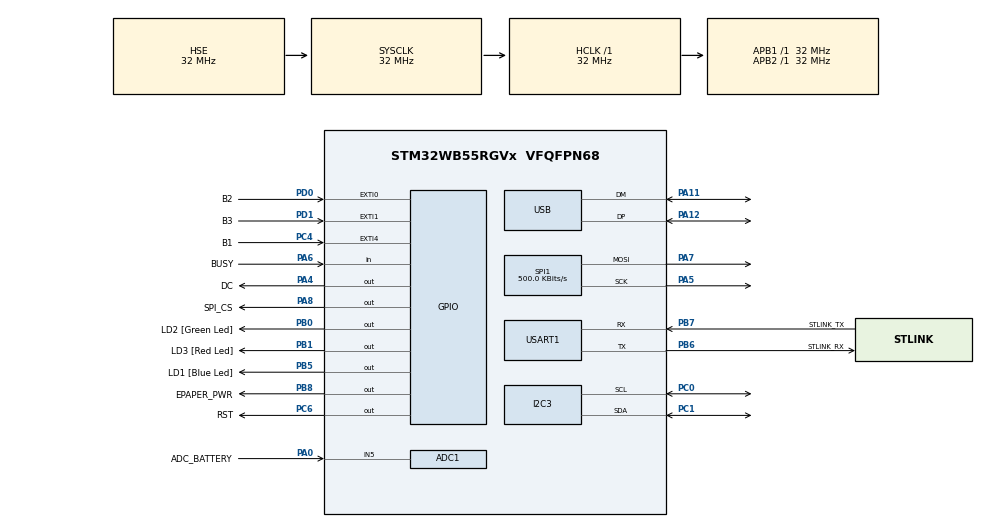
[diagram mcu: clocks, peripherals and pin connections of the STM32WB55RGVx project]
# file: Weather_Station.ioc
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ADC1.Channel-0\#ChannelRegularConversion=ADC_CHANNEL_5
ADC1.LowPowerAutoWait=ENABLE
ADC1.NbrOfConversionFlag=1
ADC1.OffsetNumber-0\#ChannelRegularConversion=ADC_OFFSET_NONE
ADC1.Overrun=ADC_OVR_DATA_OVERWRITTEN
ADC1.Rank-0\#ChannelRegularConversion=1
ADC1.SamplingTime-0\#ChannelRegularConversion=ADC_SAMPLETIME_2CYCLES_5
ADC1.master=1
Dma.Request0=USART1_RX
Dma.USART1_RX.0.Direction=DMA_PERIPH_TO_MEMORY
Dma.USART1_RX.0.EventEnable=DISABLE
Dma.USART1_RX.0.Instance=DMA1_Channel1
Dma.USART1_RX.0.MemDataAlignment=DMA_MDATAALIGN_BYTE
Dma.USART1_RX.0.MemInc=DMA_MINC_ENABLE
Dma.USART1_RX.0.Mode=DMA_NORMAL
Dma.USART1_RX.0.PeriphDataAlignment=DMA_PDATAALIGN_BYTE
Dma.USART1_RX.0.PeriphInc=DMA_PINC_DISABLE
Dma.USART1_RX.0.Polarity=HAL_DMAMUX_REQ_GEN_RISING
Dma.USART1_RX.0.Priority=DMA_PRIORITY_LOW
Dma.USART1_RX.0.RequestNumber=1
Dma.USART1_RX.0.SignalID=NONE
Dma.USART1_RX.0.SyncEnable=DISABLE
Dma.USART1_RX.0.SyncPolarity=HAL_DMAMUX_SYNC_NO_EVENT
Dma.USART1_RX.0.SyncRequestNumber=1
Dma.USART1_RX.0.SyncSignalID=NONE
I2C3.Timing=0x00707CBB
Mcu.Family=STM32WB
Mcu.Name=STM32WB55RGVx
Mcu.Package=VFQFPN68
NVIC.DMA1_Channel1_IRQn=true\:0\:0\:false\:false\:true\:false\:true\:true
NVIC.EXTI0_IRQn=true\:0\:1\:false\:false\:true\:true\:true\:true
NVIC.EXTI1_IRQn=true\:0\:1\:false\:false\:true\:true\:true\:true
NVIC.EXTI4_IRQn=true\:0\:1\:false\:false\:true\:true\:true\:true
NVIC.PriorityGroup=NVIC_PRIORITYGROUP_3
NVIC.RTC_Alarm_IRQn=true\:2\:1\:true\:true\:true\:1\:true\:true\:true
NVIC.TIM1_TRG_COM_TIM17_IRQn=true\:1\:0\:true\:false\:true\:true\:true\:true
NVIC.USART1_IRQn=true\:1\:1\:true\:false\:true\:true\:true\:true
OSC_IN.Mode=HSE-External-Oscillator
OSC_IN.Signal=RCC_OSC_IN
OSC_OUT.Mode=HSE-External-Oscillator
OSC_OUT.Signal=RCC_OSC_OUT
PA0.GPIO_Label=ADC_BATTERY
PA0.Signal=ADCx_IN5
PA11.Mode=Device
PA11.Signal=USB_DM
PA12.Mode=Device
PA12.Signal=USB_DP
PA13.GPIO_Label=JTMS
PA13.Mode=Trace_Asynchronous_SW
PA13.Signal=SYS_JTMS-SWDIO
PA14.GPIO_Label=JTCK
PA14.Mode=Trace_Asynchronous_SW
PA14.Signal=SYS_JTCK-SWCLK
PA4.GPIO_Label=DC
PA4.Signal=GPIO_Output
PA5.Mode=TX_Only_Simplex_Unidirect_Master
PA5.Signal=SPI1_SCK
PA6.GPIO_Label=BUSY
PA6.Signal=GPIO_Input
PA7.Mode=TX_Only_Simplex_Unidirect_Master
PA7.Signal=SPI1_MOSI
PA8.GPIO_Label=SPI_CS
PA8.Signal=GPIO_Output
PB0.GPIO_Label=LD2 [Green Led]
PB0.Signal=GPIO_Output
PB1.GPIO_Label=LD3 [Red Led]
PB1.Signal=GPIO_Output
PB3.GPIO_Label=JTDO
PB3.Mode=Trace_Asynchronous_SW
PB3.Signal=SYS_JTDO-SWO
PB5.GPIO_Label=LD1 [Blue Led]
PB5.Signal=GPIO_Output
PB6.GPIO_Label=STLINK_RX
PB6.GPIO_PuPd=GPIO_PULLUP
PB6.Mode=Asynchronous
PB6.Signal=USART1_TX
PB7.GPIO_Label=STLINK_TX
PB7.GPIO_PuPd=GPIO_PULLUP
PB7.Mode=Asynchronous
PB7.Signal=USART1_RX
PB8.GPIO_Label=EPAPER_PWR
PB8.Signal=GPIO_Output
PC0.Mode=I2C
PC0.Signal=I2C3_SCL
PC1.Mode=I2C
PC1.Signal=I2C3_SDA
PC13.Mode=SYS_WakeUp1
PC13.Signal=SYS_WKUP2
PC14-OSC32_IN.Mode=LSE-External-Oscillator
PC14-OSC32_IN.Signal=RCC_OSC32_IN
PC15-OSC32_OUT.Mode=LSE-External-Oscillator
PC15-OSC32_OUT.Signal=RCC_OSC32_OUT
PC4.GPIO_Label=B1
PC4.GPIO_ModeDefaultEXTI=GPIO_MODE_IT_FALLING
PC4.GPIO_PuPd=GPIO_PULLUP
PC4.Signal=GPXTI4
PC6.GPIO_Label=RST
PC6.GPIO_PuPd=GPIO_NOPULL
PC6.Signal=GPIO_Output
PD0.GPIO_Label=B2
PD0.GPIO_PuPd=GPIO_PULLUP
PD0.Signal=GPXTI0
PD1.GPIO_Label=B3
PD1.GPIO_PuPd=GPIO_PULLUP
PD1.Signal=GPXTI1
ProjectManager.HeapSize=0x200
ProjectManager.StackSize=0x400
ProjectManager.TargetToolchain=STM32CubeIDE
RCC.ADCFreq_Value=48000000
RCC.AHBFreq_Value=32000000
RCC.APB1Freq_Value=32000000
RCC.APB1TimFreq_Value=32000000
RCC.APB2Freq_Value=32000000
RCC.APB2TimFreq_Value=32000000
RCC.APB3Freq_Value=16000000
RCC.CortexFreq_Value=32000000
RCC.HCLKFreq_Value=32000000
RCC.HSE_VALUE=32000000
RCC.HSI48_VALUE=48000000
RCC.HSI_VALUE=16000000
RCC.LSE_Drive_Capability=RCC_LSEDRIVE_LOW
RCC.PLLN=32
RCC.PLLSAI1N=24
RCC.SMPSCLockSelectionVirtual=RCC_SMPSCLKSOURCE_HSI
RCC.SMPSCLockSelectionVirtualVirtual=RCC_SMPSCLKSOURCE_HSI
RCC.SMPSDivider=1
RCC.SYSCLKFreq_VALUE=32000000
RCC.SYSCLKSource=RCC_SYSCLKSOURCE_HSE
RCC.USBFreq_Value=48000000
RCC.VCOOutputFreq_Value=128000000
RTC.Alarm-Alarm\ A=RTC_ALARM_A
RTC.AlarmMaskDateWeekDay-Alarm\ A=RTC_ALARMMASK_DATEWEEKDAY
RTC.AlarmMaskHours-Alarm\ A=RTC_ALARMMASK_HOURS
RTC.AlarmMaskMinutes-Alarm\ A=RTC_ALARMMASK_MINUTES
RTC.Format=RTC_FORMAT_BIN
RTC.Seconds_A-Alarm\ A=5
SH.ADCx_IN5.0=ADC1_IN5,IN5-Single-Ended
SPI1.BaudRatePrescaler=SPI_BAUDRATEPRESCALER_64
SPI1.CalculateBaudRate=500.0 KBits/s
SPI1.DataSize=SPI_DATASIZE_8BIT
SPI1.Direction=SPI_DIRECTION_2LINES
SPI1.Mode=SPI_MODE_MASTER
SPI1.VirtualType=VM_MASTER
TIM17.Period=10000
TIM17.Prescaler=32000-1
USART1.VirtualMode-Asynchronous=VM_ASYNC
USART1.WordLength=WORDLENGTH_8B
VP_MEMORYMAP_VS_MEMORYMAP.Mode=CurAppReg
VP_RTC_VS_RTC_Activate.Mode=RTC_Enabled
VP_RTC_VS_RTC_Alarm_A_Intern.Mode=Alarm A
VP_RTC_VS_RTC_Calendar.Mode=RTC_Calendar
VP_TIM17_VS_ClockSourceINT.Mode=Enable_Timer
board=NUCLEO-WB55RG

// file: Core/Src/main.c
/* USER CODE BEGIN Header */
/**
  ******************************************************************************
  * @file           : main.c
  * @brief          : Main program body
  ******************************************************************************
  * @attention
  *
  * Copyright (c) 2024 STMicroelectronics.
  * All rights reserved.
  *
  * This software is licensed under terms that can be found in the LICENSE file
  * in the root directory of this software component.
  * If no LICENSE file comes with this software, it is provided AS-IS.
  *
  ******************************************************************************
  */
/* USER CODE END Header */
#include "main.h"
#include "adc.h"
#include "dma.h"
#include "i2c.h"
#include "memorymap.h"
#include "rtc.h"
#include "spi.h"
#include "tim.h"
#include "usart.h"
#include "usb.h"
#include "gpio.h"

/* USER CODE BEGIN Includes */

#include "low_power.h"
#include "../epaper/epaper_functions.h"
#include "service_UART.h"

/* USER CODE END Includes */

void SystemClock_Config(void);
void PeriphCommonClock_Config(void);
static void MX_NVIC_Init(void);

int main(void)
{

  /* MCU Configuration--------------------------------------------------------*/

  /* Reset of all peripherals, Initializes the Flash interface and the Systick. */
  HAL_Init();

  /* Configure the system clock */
  SystemClock_Config();

/* Configure the peripherals common clocks */
  PeriphCommonClock_Config();

  /* Initialize all configured peripherals */
  MX_GPIO_Init();
  MX_DMA_Init();
  MX_USART1_UART_Init();
  MX_USB_PCD_Init();
  MX_RTC_Init();
  MX_TIM17_Init();
  MX_SPI1_Init();
  MX_I2C3_Init();
  MX_ADC1_Init();

  /* Initialize interrupts */
  MX_NVIC_Init();
  /* USER CODE BEGIN 2 */

  rtc_init();
  EpaperINIT();
  service_init();

  /* USER CODE END 2 */

  /* Infinite loop */
  /* USER CODE BEGIN WHILE */
  while (1)
  {

	  epaper_state_machine();

	  service();

	  low_power_mode();

    /* USER CODE END WHILE */

  }
}

void SystemClock_Config(void)
{
  RCC_OscInitTypeDef RCC_OscInitStruct = {0};
  RCC_ClkInitTypeDef RCC_ClkInitStruct = {0};

  /** Macro to configure the PLL multiplication factor
  */
  __HAL_RCC_PLL_PLLM_CONFIG(RCC_PLLM_DIV1);

  /** Macro to configure the PLL clock source
  */
  __HAL_RCC_PLL_PLLSOURCE_CONFIG(RCC_PLLSOURCE_MSI);

  /** Configure LSE Drive Capability
  */
  HAL_PWR_EnableBkUpAccess();
  __HAL_RCC_LSEDRIVE_CONFIG(RCC_LSEDRIVE_LOW);

  /** Configure the main internal regulator output voltage
  */
  __HAL_PWR_VOLTAGESCALING_CONFIG(PWR_REGULATOR_VOLTAGE_SCALE1);

  /** Initializes the RCC Oscillators according to the specified parameters
  * in the RCC_OscInitTypeDef structure.
  */
  RCC_OscInitStruct.OscillatorType = RCC_OSCILLATORTYPE_HSI|RCC_OSCILLATORTYPE_LSI1
                              |RCC_OSCILLATORTYPE_HSE|RCC_OSCILLATORTYPE_LSE
                              |RCC_OSCILLATORTYPE_MSI;
  RCC_OscInitStruct.HSEState = RCC_HSE_ON;
  RCC_OscInitStruct.LSEState = RCC_LSE_ON;
  RCC_OscInitStruct.HSIState = RCC_HSI_ON;
  RCC_OscInitStruct.MSIState = RCC_MSI_ON;
  RCC_OscInitStruct.HSICalibrationValue = RCC_HSICALIBRATION_DEFAULT;
  RCC_OscInitStruct.MSICalibrationValue = RCC_MSICALIBRATION_DEFAULT;
  RCC_OscInitStruct.MSIClockRange = RCC_MSIRANGE_6;
  RCC_OscInitStruct.LSIState = RCC_LSI_ON;
  RCC_OscInitStruct.PLL.PLLState = RCC_PLL_NONE;
  if (HAL_RCC_OscConfig(&RCC_OscInitStruct) != HAL_OK)
  {
    Error_Handler();
  }

  /** Configure the SYSCLKSource, HCLK, PCLK1 and PCLK2 clocks dividers
  */
  RCC_ClkInitStruct.ClockType = RCC_CLOCKTYPE_HCLK4|RCC_CLOCKTYPE_HCLK2
                              |RCC_CLOCKTYPE_HCLK|RCC_CLOCKTYPE_SYSCLK
                              |RCC_CLOCKTYPE_PCLK1|RCC_CLOCKTYPE_PCLK2;
  RCC_ClkInitStruct.SYSCLKSource = RCC_SYSCLKSOURCE_HSE;
  RCC_ClkInitStruct.AHBCLKDivider = RCC_SYSCLK_DIV1;
  RCC_ClkInitStruct.APB1CLKDivider = RCC_HCLK_DIV1;
  RCC_ClkInitStruct.APB2CLKDivider = RCC_HCLK_DIV1;
  RCC_ClkInitStruct.AHBCLK2Divider = RCC_SYSCLK_DIV1;
  RCC_ClkInitStruct.AHBCLK4Divider = RCC_SYSCLK_DIV1;

  if (HAL_RCC_ClockConfig(&RCC_ClkInitStruct, FLASH_LATENCY_1) != HAL_OK)
  {
    Error_Handler();
  }

  /** Enable MSI Auto calibration
  */
  HAL_RCCEx_EnableMSIPLLMode();
}

void PeriphCommonClock_Config(void)
{
  RCC_PeriphCLKInitTypeDef PeriphClkInitStruct = {0};

  /** Initializes the peripherals clock
  */
  PeriphClkInitStruct.PeriphClockSelection = RCC_PERIPHCLK_SMPS|RCC_PERIPHCLK_USB
                              |RCC_PERIPHCLK_ADC;
  PeriphClkInitStruct.PLLSAI1.PLLN = 24;
  PeriphClkInitStruct.PLLSAI1.PLLP = RCC_PLLP_DIV2;
  PeriphClkInitStruct.PLLSAI1.PLLQ = RCC_PLLQ_DIV2;
  PeriphClkInitStruct.PLLSAI1.PLLR = RCC_PLLR_DIV2;
  PeriphClkInitStruct.PLLSAI1.PLLSAI1ClockOut = RCC_PLLSAI1_USBCLK|RCC_PLLSAI1_ADCCLK;
  PeriphClkInitStruct.UsbClockSelection = RCC_USBCLKSOURCE_PLLSAI1;
  PeriphClkInitStruct.AdcClockSelection = RCC_ADCCLKSOURCE_PLLSAI1;
  PeriphClkInitStruct.SmpsClockSelection = RCC_SMPSCLKSOURCE_HSI;
  PeriphClkInitStruct.SmpsDivSelection = RCC_SMPSCLKDIV_RANGE0;

  if (HAL_RCCEx_PeriphCLKConfig(&PeriphClkInitStruct) != HAL_OK)
  {
    Error_Handler();
  }
}

/**
  * @brief NVIC Configuration.
  * @retval None
  */
static void MX_NVIC_Init(void)
{
  /* RTC_Alarm_IRQn interrupt configuration */
  HAL_NVIC_SetPriority(RTC_Alarm_IRQn, 2, 1);
  HAL_NVIC_EnableIRQ(RTC_Alarm_IRQn);
}

void Error_Handler(void)
{
  __disable_irq();
  while (1)
  {
  }
}
